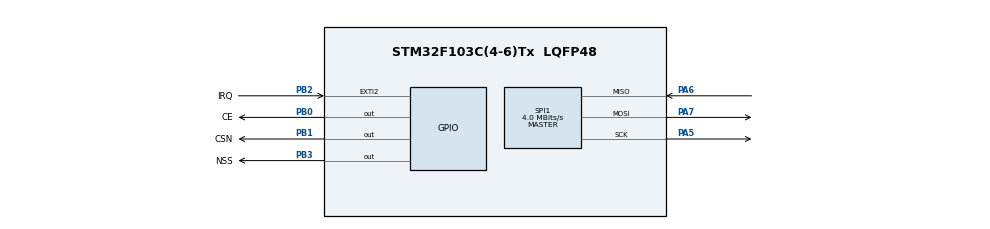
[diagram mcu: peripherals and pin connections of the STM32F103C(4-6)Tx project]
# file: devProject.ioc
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Mcu.Family=STM32F1
Mcu.Name=STM32F103C(4-6)Tx
Mcu.Package=LQFP48
NVIC.EXTI2_IRQn=true\:0\:0\:false\:false\:true\:true\:true\:true
NVIC.PriorityGroup=NVIC_PRIORITYGROUP_4
PA13.Mode=Serial_Wire
PA13.Signal=SYS_JTMS-SWDIO
PA14.Mode=Serial_Wire
PA14.Signal=SYS_JTCK-SWCLK
PA5.Mode=Full_Duplex_Master
PA5.Signal=SPI1_SCK
PA6.Mode=Full_Duplex_Master
PA6.Signal=SPI1_MISO
PA7.Mode=Full_Duplex_Master
PA7.Signal=SPI1_MOSI
PB0.GPIO_Label=CE
PB0.GPIO_Speed=GPIO_SPEED_FREQ_HIGH
PB0.Signal=GPIO_Output
PB1.GPIO_Label=CSN
PB1.GPIO_Speed=GPIO_SPEED_FREQ_HIGH
PB1.PinState=GPIO_PIN_SET
PB1.Signal=GPIO_Output
PB2.GPIO_Label=IRQ
PB2.GPIO_ModeDefaultEXTI=GPIO_MODE_IT_FALLING
PB2.Signal=GPXTI2
PB3.GPIO_Label=NSS
PB3.Signal=GPIO_Output
PD0-OSC_IN.Mode=HSE-External-Oscillator
PD0-OSC_IN.Signal=RCC_OSC_IN
PD1-OSC_OUT.Mode=HSE-External-Oscillator
PD1-OSC_OUT.Signal=RCC_OSC_OUT
ProjectManager.HeapSize=0x200
ProjectManager.StackSize=0x400
ProjectManager.TargetToolchain=STM32CubeIDE
RCC.APB1Freq_Value=8000000
RCC.APB2Freq_Value=8000000
SPI1.CalculateBaudRate=4.0 MBits/s
SPI1.Direction=SPI_DIRECTION_2LINES
SPI1.Mode=SPI_MODE_MASTER
SPI1.VirtualType=VM_MASTER
board=custom

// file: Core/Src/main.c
/* USER CODE BEGIN Header */
/**
  ******************************************************************************
  * @file           : main.c
  * @brief          : Main program body
  ******************************************************************************
  * @attention
  *
  * Copyright (c) 2024 STMicroelectronics.
  * All rights reserved.
  *
  * This software is licensed under terms that can be found in the LICENSE file
  * in the root directory of this software component.
  * If no LICENSE file comes with this software, it is provided AS-IS.
  *
  ******************************************************************************
  */
/* USER CODE END Header */
#include "main.h"
#include "spi.h"
#include "gpio.h"

/* USER CODE BEGIN Includes */
#include "nrf24l01p.h"
/* USER CODE END Includes */

void SystemClock_Config(void);
/* USER CODE BEGIN PFP */
void HAL_GPIO_EXTI_Callback(uint16_t GPIO_Pin);
/* USER CODE END PFP */

/* USER CODE BEGIN 0 */

// TRANSMITTER CODE SESSION

uint8_t tx_data[NRF24L01P_PAYLOAD_LENGTH] = {0, 1, 2, 3, 4, 5, 6, 7};

/* USER CODE END 0 */

int main(void)
{

  /* MCU Configuration--------------------------------------------------------*/

  /* Reset of all peripherals, Initializes the Flash interface and the Systick. */
  HAL_Init();

  /* Configure the system clock */
  SystemClock_Config();

  /* Initialize all configured peripherals */
  MX_GPIO_Init();
  MX_SPI1_Init();
  /* USER CODE BEGIN 2 */

  nrf24l01p_tx_init(2500, _1Mbps);

  // RECEIVER CODE SESSION

  /* USER CODE END 2 */

  /* Infinite loop */
  /* USER CODE BEGIN WHILE */
  while (1)
  {
	  for(int i= 0; i < 8; i++)
		  tx_data[i]++;

	  // transmit
	  nrf24l01p_tx_transmit(tx_data);
	  HAL_Delay(10);

    /* USER CODE END WHILE */

  }
}

void SystemClock_Config(void)
{
  RCC_OscInitTypeDef RCC_OscInitStruct = {0};
  RCC_ClkInitTypeDef RCC_ClkInitStruct = {0};

  /** Configure the main internal regulator output voltage
  */
  __HAL_RCC_PWR_CLK_ENABLE();
  __HAL_PWR_VOLTAGESCALING_CONFIG(PWR_REGULATOR_VOLTAGE_SCALE1);

  /** Initializes the RCC Oscillators according to the specified parameters
  * in the RCC_OscInitTypeDef structure.
  */
  RCC_OscInitStruct.OscillatorType = RCC_OSCILLATORTYPE_HSI;
  RCC_OscInitStruct.HSIState = RCC_HSI_ON;
  RCC_OscInitStruct.HSICalibrationValue = RCC_HSICALIBRATION_DEFAULT;
  RCC_OscInitStruct.PLL.PLLState = RCC_PLL_NONE;
  if (HAL_RCC_OscConfig(&RCC_OscInitStruct) != HAL_OK)
  {
    Error_Handler();
  }

  /** Initializes the CPU, AHB and APB buses clocks
  */
  RCC_ClkInitStruct.ClockType = RCC_CLOCKTYPE_HCLK|RCC_CLOCKTYPE_SYSCLK
                              |RCC_CLOCKTYPE_PCLK1|RCC_CLOCKTYPE_PCLK2;
  RCC_ClkInitStruct.SYSCLKSource = RCC_SYSCLKSOURCE_HSI;
  RCC_ClkInitStruct.AHBCLKDivider = RCC_SYSCLK_DIV1;
  RCC_ClkInitStruct.APB1CLKDivider = RCC_HCLK_DIV1;
  RCC_ClkInitStruct.APB2CLKDivider = RCC_HCLK_DIV1;

  if (HAL_RCC_ClockConfig(&RCC_ClkInitStruct, FLASH_LATENCY_0) != HAL_OK)
  {
    Error_Handler();
  }
}

/* USER CODE BEGIN 4 */
void HAL_GPIO_EXTI_Callback(uint16_t GPIO_Pin)
{
	if(GPIO_Pin == NRF24L01P_IRQ_PIN_NUMBER)
		nrf24l01p_tx_irq(); // clear interrupt flag
}
/* USER CODE END 4 */

void Error_Handler(void)
{
  __disable_irq();
  while (1)
  {
  }
}
